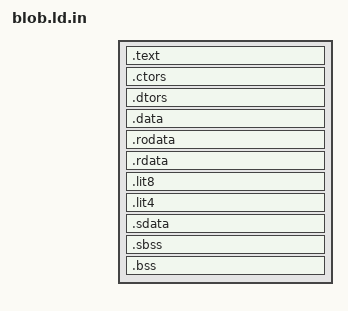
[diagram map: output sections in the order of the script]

/* Include the api ld script file which tells ld addresses */
INCLUDE ../europa_api/ld/@REGION@.ld

/* TODO this does have to be aligned to a 0x4/0x10 boundary */
BLOB_LOAD_ADDRESS = __HOOK_ORIG_END + 0xFD0;

SECTIONS {

	. = BLOB_LOAD_ADDRESS;
	_begin = BLOB_LOAD_ADDRESS;

	/* Alias ml memory allocation directly, since
	 these functions are ABI compatiable. Saves some space */
	mlMalloc = malloc;
	mlFree = free;

	.text ALIGN(4) : {
		*(.text)
		*(.text.*)
    	*(.gnu.linkonce.t*)
    	. = ALIGN(4);
	}

	.ctors : {
		KEEP (*crtbegin.o(.ctors))
		KEEP (*(EXCLUDE_FILE (*crtend.o) .ctors))
	    KEEP (*(SORT(.ctors.*)))
		KEEP (*(.ctors))	
	}
	
  	.dtors : {
		KEEP (*crtbegin.o(.dtors))
		KEEP (*(EXCLUDE_FILE (*crtend.o) .dtors))
		KEEP (*(SORT(.dtors.*)))
		KEEP (*(.dtors))
  	}

	/DISCARD/ : {
		/* Ignore .reginfo. It is not needed and adds bloat */
		*(.reginfo)
	}

	.data : { 
		*(.data)
		*(.data.*)
    	*(.gnu.linkonce.d*)
    	. = ALIGN(4);
	 }

	.rodata : {
		*(.rodata)
		*(.rodata.*)
		*(.gnu.linkonce.r*)
		. = ALIGN(4);
	}
	.rdata : { *(.rdata) }
	.lit8 : { *(.lit8) }
	.lit4 : { *(.lit4) }
	.sdata : { *(.sdata) }
	.sbss : { _fbss = .; *(.sbss) *(.scommon) }
	.bss : { *(.bss) }

	. = ALIGN(4);
	_end = .;
}
